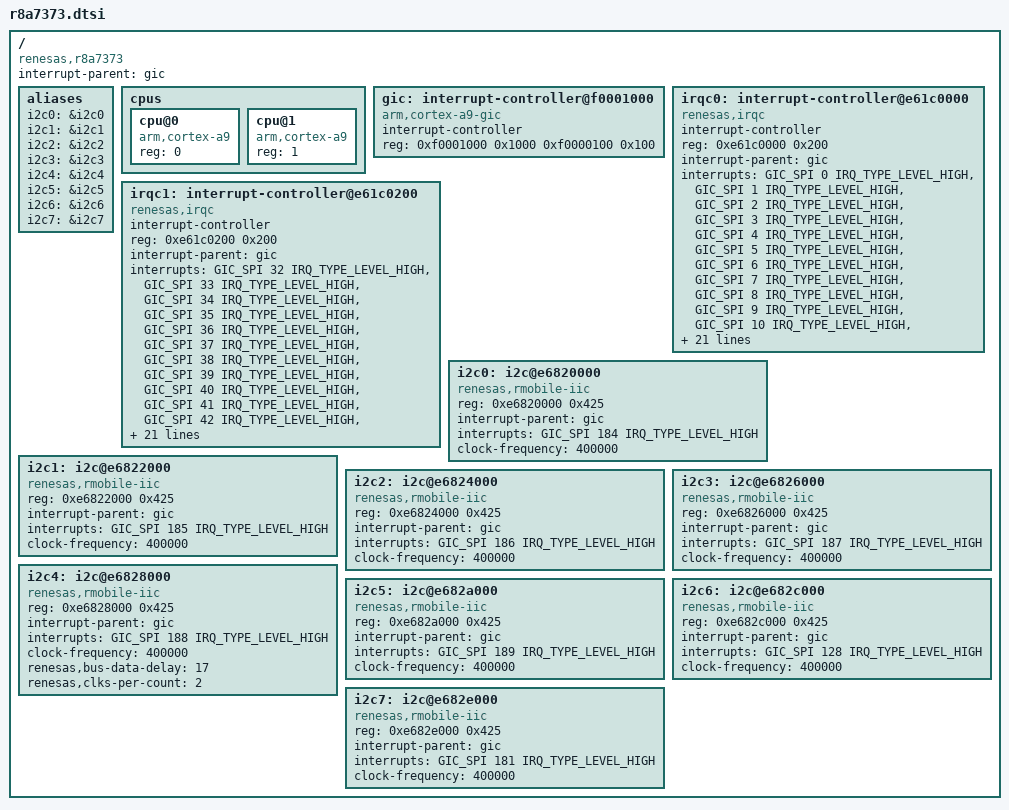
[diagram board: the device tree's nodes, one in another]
/*
 * Device Tree Source for the r8a7373 based loganlte board
 *
 * Copyright (C) 2013 Renesas Mobile
 *
 * This file is licensed under the terms of the GNU General Public License
 * version 2.  This program is licensed "as is" without any warranty of any
 * kind, whether express or implied.
 */

/include/ "skeleton.dtsi"

#include <dt-bindings/interrupt-controller/arm-gic.h>
#include <dt-bindings/interrupt-controller/irq.h>

/{
	compatible = "renesas,r8a7373";
	interrupt-parent = <&gic>;
	#address-cells = <1>;
	#size-cells = <1>;

	aliases {
		i2c0 = &i2c0;
		i2c1 = &i2c1;
		i2c2 = &i2c2;
		i2c3 = &i2c3;
		i2c4 = &i2c4;
		i2c5 = &i2c5;
		i2c6 = &i2c6;
		i2c7 = &i2c7;
	};

	cpus {
		#address-cells = <1>;
		#size-cells = <0>;

		cpu@0 {
			device_type = "cpu";
			compatible = "arm,cortex-a9";
			reg = <0>;
		};

		cpu@1 {
			device_type = "cpu";
			compatible = "arm,cortex-a9";
			reg = <1>;
		};
	};

	gic: interrupt-controller@f0001000 {
		compatible = "arm,cortex-a9-gic";
		interrupt-controller;
		reg = <0xf0001000 0x1000
		       0xf0000100 0x100>;
		#interrupt-cells = <3>;
	};

	irqc0: interrupt-controller@e61c0000 {
		compatible = "renesas,irqc";
		#interrupt-cells = <2>;
		interrupt-controller;
		reg = <0xe61c0000 0x200>;
		interrupt-parent = <&gic>;
		interrupts = <GIC_SPI 0 IRQ_TYPE_LEVEL_HIGH>,
			     <GIC_SPI 1 IRQ_TYPE_LEVEL_HIGH>,
			     <GIC_SPI 2 IRQ_TYPE_LEVEL_HIGH>,
			     <GIC_SPI 3 IRQ_TYPE_LEVEL_HIGH>,
			     <GIC_SPI 4 IRQ_TYPE_LEVEL_HIGH>,
			     <GIC_SPI 5 IRQ_TYPE_LEVEL_HIGH>,
			     <GIC_SPI 6 IRQ_TYPE_LEVEL_HIGH>,
			     <GIC_SPI 7 IRQ_TYPE_LEVEL_HIGH>,
			     <GIC_SPI 8 IRQ_TYPE_LEVEL_HIGH>,
			     <GIC_SPI 9 IRQ_TYPE_LEVEL_HIGH>,
			     <GIC_SPI 10 IRQ_TYPE_LEVEL_HIGH>,
			     <GIC_SPI 11 IRQ_TYPE_LEVEL_HIGH>,
			     <GIC_SPI 12 IRQ_TYPE_LEVEL_HIGH>,
			     <GIC_SPI 13 IRQ_TYPE_LEVEL_HIGH>,
			     <GIC_SPI 14 IRQ_TYPE_LEVEL_HIGH>,
			     <GIC_SPI 15 IRQ_TYPE_LEVEL_HIGH>,
			     <GIC_SPI 16 IRQ_TYPE_LEVEL_HIGH>,
			     <GIC_SPI 17 IRQ_TYPE_LEVEL_HIGH>,
			     <GIC_SPI 18 IRQ_TYPE_LEVEL_HIGH>,
			     <GIC_SPI 19 IRQ_TYPE_LEVEL_HIGH>,
			     <GIC_SPI 20 IRQ_TYPE_LEVEL_HIGH>,
			     <GIC_SPI 21 IRQ_TYPE_LEVEL_HIGH>,
			     <GIC_SPI 22 IRQ_TYPE_LEVEL_HIGH>,
			     <GIC_SPI 23 IRQ_TYPE_LEVEL_HIGH>,
			     <GIC_SPI 24 IRQ_TYPE_LEVEL_HIGH>,
			     <GIC_SPI 25 IRQ_TYPE_LEVEL_HIGH>,
			     <GIC_SPI 26 IRQ_TYPE_LEVEL_HIGH>,
			     <GIC_SPI 27 IRQ_TYPE_LEVEL_HIGH>,
			     <GIC_SPI 28 IRQ_TYPE_LEVEL_HIGH>,
			     <GIC_SPI 29 IRQ_TYPE_LEVEL_HIGH>,
			     <GIC_SPI 30 IRQ_TYPE_LEVEL_HIGH>,
			     <GIC_SPI 31 IRQ_TYPE_LEVEL_HIGH>;
	};

	irqc1: interrupt-controller@e61c0200 {
		compatible = "renesas,irqc";
		#interrupt-cells = <2>;
		interrupt-controller;
		reg = <0xe61c0200 0x200>;
		interrupt-parent = <&gic>;
		interrupts = <GIC_SPI 32 IRQ_TYPE_LEVEL_HIGH>,
			     <GIC_SPI 33 IRQ_TYPE_LEVEL_HIGH>,
			     <GIC_SPI 34 IRQ_TYPE_LEVEL_HIGH>,
			     <GIC_SPI 35 IRQ_TYPE_LEVEL_HIGH>,
			     <GIC_SPI 36 IRQ_TYPE_LEVEL_HIGH>,
			     <GIC_SPI 37 IRQ_TYPE_LEVEL_HIGH>,
			     <GIC_SPI 38 IRQ_TYPE_LEVEL_HIGH>,
			     <GIC_SPI 39 IRQ_TYPE_LEVEL_HIGH>,
			     <GIC_SPI 40 IRQ_TYPE_LEVEL_HIGH>,
			     <GIC_SPI 41 IRQ_TYPE_LEVEL_HIGH>,
			     <GIC_SPI 42 IRQ_TYPE_LEVEL_HIGH>,
			     <GIC_SPI 43 IRQ_TYPE_LEVEL_HIGH>,
			     <GIC_SPI 44 IRQ_TYPE_LEVEL_HIGH>,
			     <GIC_SPI 45 IRQ_TYPE_LEVEL_HIGH>,
			     <GIC_SPI 46 IRQ_TYPE_LEVEL_HIGH>,
			     <GIC_SPI 47 IRQ_TYPE_LEVEL_HIGH>,
			     <GIC_SPI 48 IRQ_TYPE_LEVEL_HIGH>,
			     <GIC_SPI 49 IRQ_TYPE_LEVEL_HIGH>,
			     <GIC_SPI 50 IRQ_TYPE_LEVEL_HIGH>,
			     <GIC_SPI 51 IRQ_TYPE_LEVEL_HIGH>,
			     <GIC_SPI 52 IRQ_TYPE_LEVEL_HIGH>,
			     <GIC_SPI 53 IRQ_TYPE_LEVEL_HIGH>,
			     <GIC_SPI 54 IRQ_TYPE_LEVEL_HIGH>,
			     <GIC_SPI 55 IRQ_TYPE_LEVEL_HIGH>,
			     <GIC_SPI 56 IRQ_TYPE_LEVEL_HIGH>,
			     <GIC_SPI 57 IRQ_TYPE_LEVEL_HIGH>,
			     <GIC_SPI 58 IRQ_TYPE_LEVEL_HIGH>,
			     <GIC_SPI 59 IRQ_TYPE_LEVEL_HIGH>,
			     <GIC_SPI 60 IRQ_TYPE_LEVEL_HIGH>,
			     <GIC_SPI 61 IRQ_TYPE_LEVEL_HIGH>,
			     <GIC_SPI 62 IRQ_TYPE_LEVEL_HIGH>,
			     <GIC_SPI 63 IRQ_TYPE_LEVEL_HIGH>;
	};

	i2c0: i2c@e6820000 {
		#address-cells = <1>;
		#size-cells = <0>;
		compatible = "renesas,rmobile-iic";
		reg = <0xe6820000 0x425>;
		interrupt-parent = <&gic>;
		interrupts = <GIC_SPI 184 IRQ_TYPE_LEVEL_HIGH>;
		clock-frequency = <400000>;
	};

	i2c1: i2c@e6822000 {
		#address-cells = <1>;
		#size-cells = <0>;
		compatible = "renesas,rmobile-iic";
		reg = <0xe6822000 0x425>;
		interrupt-parent = <&gic>;
		interrupts = <GIC_SPI 185 IRQ_TYPE_LEVEL_HIGH>;
		clock-frequency = <400000>;
	};

	i2c2: i2c@e6824000 {
		#address-cells = <1>;
		#size-cells = <0>;
		compatible = "renesas,rmobile-iic";
		reg = <0xe6824000 0x425>;
		interrupt-parent = <&gic>;
		interrupts = <GIC_SPI 186 IRQ_TYPE_LEVEL_HIGH>;
		clock-frequency = <400000>;
	};

	i2c3: i2c@e6826000 {
		#address-cells = <1>;
		#size-cells = <0>;
		compatible = "renesas,rmobile-iic";
		reg = <0xe6826000 0x425>;
		interrupt-parent = <&gic>;
		interrupts = <GIC_SPI 187 IRQ_TYPE_LEVEL_HIGH>;
		clock-frequency = <400000>;
	};

	i2c4: i2c@e6828000 {
		#address-cells = <1>;
		#size-cells = <0>;
		compatible = "renesas,rmobile-iic";
		reg = <0xe6828000 0x425>;
		interrupt-parent = <&gic>;
		interrupts = <GIC_SPI 188 IRQ_TYPE_LEVEL_HIGH>;
		clock-frequency = <400000>;
		renesas,bus-data-delay = <17>;
		renesas,clks-per-count = <2>;
	};


	i2c5: i2c@e682a000 {
		#address-cells = <1>;
		#size-cells = <0>;
		compatible = "renesas,rmobile-iic";
		reg = <0xe682a000 0x425>;
		interrupt-parent = <&gic>;
		interrupts = <GIC_SPI 189 IRQ_TYPE_LEVEL_HIGH>;
		clock-frequency = <400000>;
	};

	i2c6: i2c@e682c000 {
		#address-cells = <1>;
		#size-cells = <0>;
		compatible = "renesas,rmobile-iic";
		reg = <0xe682c000 0x425>;
		interrupt-parent = <&gic>;
		interrupts = <GIC_SPI 128 IRQ_TYPE_LEVEL_HIGH>;
		clock-frequency = <400000>;
	};

	i2c7: i2c@e682e000 {
		#address-cells = <1>;
		#size-cells = <0>;
		compatible = "renesas,rmobile-iic";
		reg = <0xe682e000 0x425>;
		interrupt-parent = <&gic>;
		interrupts = <GIC_SPI 181 IRQ_TYPE_LEVEL_HIGH>;
		clock-frequency = <400000>;
	};
 };
